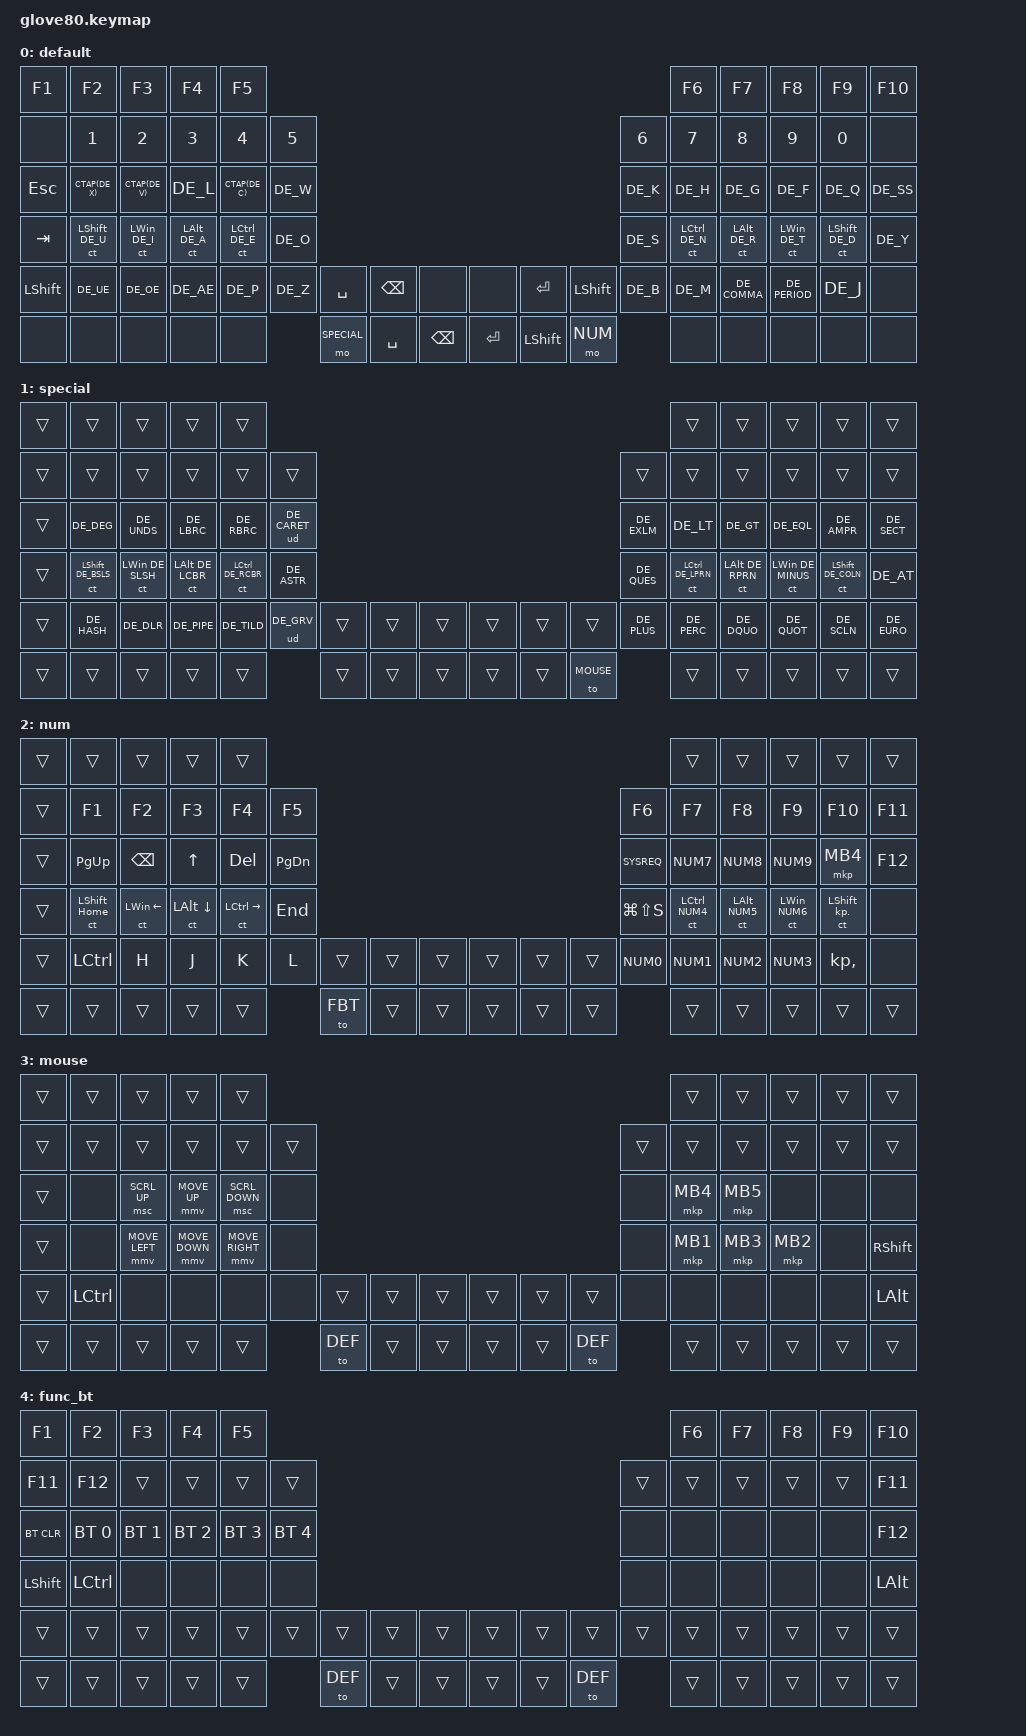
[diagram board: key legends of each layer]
/*
 * Copyright (c) 2020 The ZMK Contributors
 *
 * SPDX-License-Identifier: MIT
 */

#include <behaviors.dtsi>
#include <dt-bindings/zmk/bt.h>
#include <dt-bindings/zmk/mouse.h>
#include <dt-bindings/zmk/keys.h>
#include <dt-bindings/zmk/pointing.h>

#include <dt-bindings/zmk/ext_power.h>
#include <dt-bindings/zmk/outputs.h>
#include <dt-bindings/zmk/rgb.h>

#include "zmk-helpers/helper.h"
// Source desired key-position labels
#include "zmk-helpers/key-labels/glove80.h"
// Source unicode-chars for desired languages
#include "zmk-helpers/unicode-chars/german.dtsi"
#include "ger_symbols.h"

/* layer and key shortcuts */

#define ___ &trans
#define XXX &none

#define NUM1 KP_NUMBER_1
#define NUM2 KP_NUMBER_2 
#define NUM3 KP_NUMBER_3
#define NUM4 KP_NUMBER_4
#define NUM5 KP_NUMBER_5 
#define NUM6 KP_NUMBER_6 
#define NUM7 KP_NUMBER_7 
#define NUM8 KP_NUMBER_8 
#define NUM9 KP_NUMBER_9 
#define NUM0 KP_NUMBER_0 

#define DEF 0  // layer shortcuts, must match order in which they are defined below
#define SPECIAL 1
#define NUM 2
#define MOUSE 3
#define FBT 4
// #define STATUS 5

/* custom behaviors */

// control-tap-behavior
ZMK_BEHAVIOR(ct, hold_tap,
    flavor = "balanced";
    tapping-term-ms = <200>;
    quick-tap-ms = <150>;
    bindings = <&kp>, <&kp>;
)

// status layer hold-tap behavior (similar to magic in standard config)
ZMK_BEHAVIOR(st, hold_tap,
    flavor = "tap-preferred";
    tapping-term-ms = <200>;
    bindings = <&mo_status>, <&rgb_ug_status_macro>;
)

/* combos */

// NUMLOCK combo 
ZMK_COMBO(numlock_combo, &kp KP_NLCK, RB1 RB4, NUM, 25)

/* macros */

// undead DE_CARET and DE_GRV
ZMK_BEHAVIOR(ud, macro_one_param,
	bindings = <&macro_param_1to1>, <&kp MACRO_PLACEHOLDER &kp SPACE>;
)

// RGB status macro
ZMK_BEHAVIOR(rgb_ug_status_macro, macro,
    bindings = <&rgb_ug RGB_STATUS>;
)


// MO to STATUS
ZMK_BEHAVIOR(mo_status, macro,
    bindings = <&mo STATUS>;
)
// COPY/CUT + PASTE macros
ZMK_BEHAVIOR(ctrl_x, macro,
    bindings = <&kp LCTRL(DE_X)>;
)
ZMK_BEHAVIOR(ctrl_c, macro,
    bindings = <&kp LCTRL(DE_C)>;
)
ZMK_BEHAVIOR(ctrl_v, macro,
    bindings = <&kp LCTRL(DE_V)>;
)

// Bluetooth profile macros
ZMK_BEHAVIOR(bt_0, macro,
    bindings = <&out OUT_BLE>, <&bt BT_SEL 0>;
)

ZMK_BEHAVIOR(bt_1, macro,
    bindings = <&out OUT_BLE>, <&bt BT_SEL 1>;
)

ZMK_BEHAVIOR(bt_2, macro,
    bindings = <&out OUT_BLE>, <&bt BT_SEL 2>;
)

ZMK_BEHAVIOR(bt_3, macro,
    bindings = <&out OUT_BLE>, <&bt BT_SEL 3>;
)

ZMK_LAYER(default,
          &kp F1        &kp F2        &kp F3        &kp F4        &kp F5                                                                                                            &kp F6        &kp F7        &kp F8        &kp F9        &kp F10
          XXX           &kp N1        &kp N2        &kp N3        &kp N4        &kp N5                                                                                &kp N6        &kp N7        &kp N8        &kp N9        &kp N0        XXX
          &kp ESC       CTAP(DE_X)    CTAP(DE_V)    &kp DE_L      CTAP(DE_C)    &kp DE_W                                                                              &kp DE_K      &kp DE_H      &kp DE_G      &kp DE_F      &kp DE_Q      &kp DE_SS 
          &kp TAB    &ct LSHIFT DE_U &ct LWIN DE_I &ct LALT DE_A &ct LCTRL DE_E &kp DE_O                                                                              &kp DE_S   &ct LCTRL DE_N &ct LALT DE_R &ct LWIN DE_T &ct LSHIFT DE_D &kp DE_Y     
          &kp LSHIFT    &kp DE_UE     &kp DE_OE     &kp DE_AE     &kp DE_P      &kp DE_Z    &kp SPACE     &kp BSPC      XXX       XXX         &kp RETURN  &kp LSHIFT  &kp DE_B      &kp DE_M      &kp DE_COMMA  &kp DE_PERIOD &kp DE_J      XXX
          XXX           XXX           XXX           XXX           XXX                       &mo SPECIAL   &kp SPACE     &kp BSPC  &kp RETURN  &kp LSHIFT  &mo NUM                   XXX           XXX           XXX           XXX           XXX
)

ZMK_LAYER(special,
          ___           ___           ___           ___           ___                                                                                                                         ___           ___           ___           ___           ___
          ___           ___           ___           ___           ___           ___                                                                                             ___           ___           ___           ___           ___           ___
          ___           &kp DE_DEG    &kp DE_UNDS   &kp DE_LBRC   &kp DE_RBRC   &ud DE_CARET                                                                                    &kp DE_EXLM   &kp DE_LT     &kp DE_GT     &kp DE_EQL    &kp DE_AMPR   &kp DE_SECT
          ___        &ct LSHIFT DE_BSLS &ct LWIN DE_SLSH &ct LALT DE_LCBR &ct LCTRL DE_RCBR &kp DE_ASTR                                                                      &kp DE_QUES &ct LCTRL DE_LPRN &ct LALT DE_RPRN &ct LWIN DE_MINUS &ct LSHIFT DE_COLN &kp DE_AT
          ___           &kp DE_HASH   &kp DE_DLR    &kp DE_PIPE   &kp DE_TILD   &ud DE_GRV    ___           ___           ___       ___         ___         ___                 &kp DE_PLUS   &kp DE_PERC   &kp DE_DQUO   &kp DE_QUOT   &kp DE_SCLN   &kp DE_EURO
          ___           ___           ___           ___           ___                         ___           ___           ___       ___         ___         &to MOUSE                         ___           ___           ___           ___           ___
)

ZMK_LAYER(num,
          ___           ___           ___           ___           ___                                                                                                                         ___           ___           ___           ___           ___
          ___           &kp F1        &kp F2        &kp F3        &kp F4        &kp F5                                                                                          &kp F6        &kp F7        &kp F8        &kp F9        &kp F10       &kp F11
          ___           &kp PG_UP     &kp BSPC      &kp UP        &kp DELETE    &kp PG_DN                                                                                       &kp SYSREQ    &kp NUM7      &kp NUM8      &kp NUM9      &mkp MB4      &kp F12
          ___        &ct LSHIFT HOME  &ct LWIN LEFT &ct LALT DOWN &ct LCTRL RIGHT &kp END                                                                                       &kp LG(LS(S)) &ct LCTRL NUM4 &ct LALT NUM5 &ct LWIN NUM6 &ct LSHIFT KP_DOT XXX      
          ___           &kp LCTRL     &kp H         &kp J         &kp K         &kp L         ___           ___           ___       ___         ___         ___                 &kp NUM0      &kp NUM1      &kp NUM2      &kp NUM3      &kp KP_COMMA  XXX        
          ___           ___           ___           ___           ___                         &to FBT       ___           ___       ___         ___         ___                               ___           ___           ___           ___           ___
)

ZMK_LAYER(mouse,
          ___           ___           ___           ___           ___                                                                                                                        ___           ___           ___           ___           ___
          ___           ___           ___           ___           ___           ___                                                                                            ___           ___           ___           ___           ___           ___
          ___           XXX           &msc SCRL_UP  &mmv MOVE_UP  &msc SCRL_DOWN XXX                                                                                           XXX           &mkp MB4      &mkp MB5      XXX           XXX           XXX  
          ___           XXX         &mmv MOVE_LEFT &mmv MOVE_DOWN &mmv MOVE_RIGHT XXX                                                                                          XXX           &mkp MB1      &mkp MB3      &mkp MB2      XXX           &kp RSHIFT    
          ___           &kp LCTRL     XXX           XXX           XXX           XXX           ___           ___           ___       ___         ___         ___                XXX           XXX           XXX           XXX           XXX           &kp LALT      
          ___           ___           ___           ___           ___                         &to DEF       ___           ___       ___         ___         &to DEF                          ___           ___           ___           ___           ___
)

ZMK_LAYER(func_bt,
          &kp F1        &kp F2        &kp F3        &kp F4        &kp F5                                                                                                                      &kp F6        &kp F7        &kp F8        &kp F9        &kp F10
          &kp F11       &kp F12       ___           ___           ___           ___                                                                                             ___           ___           ___           ___           ___           &kp F11
          &bt BT_CLR    &bt BT_SEL 0  &bt BT_SEL 1  &bt BT_SEL 2  &bt BT_SEL 3  &bt BT_SEL 4                                                                                    XXX           XXX           XXX           XXX           XXX           &kp F12 
          &kp LSHIFT    &kp LCTRL     XXX           XXX           XXX           XXX                                                                                             XXX           XXX           XXX           XXX           XXX           &kp LALT
          ___           ___           ___           ___           ___           ___           ___           ___           ___       ___         ___         ___                 ___           ___           ___           ___           ___           ___
          ___           ___           ___           ___           ___                         &to DEF       ___           ___       ___         ___         &to DEF                           ___           ___           ___           ___           ___
)

/*
ZMK_LAYER(status,
          &bt BT_CLR    XXX           XXX           XXX           XXX                                                                                                                         XXX           XXX           XXX           XXX           &bt BT_CLR_ALL
          XXX           XXX           XXX           XXX           XXX           XXX                                                                                             XXX           XXX           XXX           XXX           XXX           XXX
          XXX           &rgb_ug RGB_SPI &rgb_ug RGB_SAI &rgb_ug RGB_HUI &rgb_ug RGB_BRI &rgb_ug RGB_TOG                                                                         XXX           XXX           XXX           XXX           XXX           XXX
          &bootloader   &rgb_ug RGB_SPD &rgb_ug RGB_SAD &rgb_ug RGB_HUD &rgb_ug RGB_BRD &rgb_ug RGB_EFF                                                                         XXX           XXX           XXX           XXX           XXX           &bootloader
          &sys_reset    XXX           XXX           XXX           XXX           XXX           &bt_2         &bt_3         ___       ___         ___         ___                 XXX           XXX           XXX           XXX           XXX           &sys_reset
          ___           XXX           XXX           XXX           XXX                         &bt_0         &bt_1         &out OUT_USB ___      ___         ___                               XXX           XXX           XXX           XXX           XXX
)
*/
